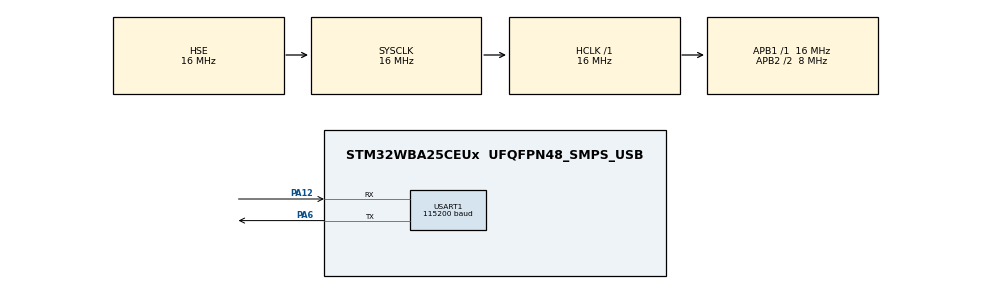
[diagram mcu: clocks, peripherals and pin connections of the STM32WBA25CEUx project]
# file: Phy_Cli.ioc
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CORTEX_M33_NS.userName=CORTEX_M33
LPDMA1.DESTINC_LPDMACH1=DMA_DINC_INCREMENTED
LPDMA1.DIRECTION_LPDMACH0=DMA_MEMORY_TO_PERIPH
LPDMA1.DIRECTION_LPDMACH1=DMA_PERIPH_TO_MEMORY
LPDMA1.IPHANDLE_LPDMACH0-SIMPLEREQUEST_LPDMACH0=__NULL
LPDMA1.IPHANDLE_LPDMACH1-SIMPLEREQUEST_LPDMACH1=__NULL
LPDMA1.REQUEST_LPDMACH0=LPDMA1_REQUEST_USART1_TX
LPDMA1.REQUEST_LPDMACH1=LPDMA1_REQUEST_USART1_RX
LPDMA1.SRCINC_LPDMACH0=DMA_SINC_INCREMENTED
Mcu.Family=STM32WBA
Mcu.Name=STM32WBA25CEUx
Mcu.Package=UFQFPN48_SMPS_USB
NVIC.LPDMA1_Channel0_IRQn=true\:6\:0\:true\:false\:true\:true\:true\:true
NVIC.LPDMA1_Channel1_IRQn=true\:2\:0\:true\:false\:true\:true\:true\:true
NVIC.PriorityGroup=NVIC_PRIORITYGROUP_4
NVIC.RADIO_IRQn=true\:0\:0\:false\:false\:true\:false\:false\:true
NVIC.RCC_IRQn=true\:1\:0\:false\:false\:true\:false\:false\:true
NVIC.RTC_IRQn=true\:4\:0\:false\:false\:true\:false\:true\:true
NVIC.USART1_IRQn=true\:7\:0\:true\:false\:true\:true\:true\:true
OSC_IN.Mode=HSE-External-Oscillator
OSC_IN.Signal=RCC_OSC_IN
OSC_OUT.Mode=HSE-External-Oscillator
OSC_OUT.Signal=RCC_OSC_OUT
PA12.GPIO_PuPd=GPIO_PULLUP
PA12.GPIO_Speed=GPIO_SPEED_FREQ_HIGH
PA12.Mode=Asynchronous
PA12.Signal=USART1_RX
PA13\ (JTMS/SWDIO).Signal=DEBUG_JTMS-SWDIO
PA14\ (JTCK/SWCLK).Signal=DEBUG_JTCK-SWCLK
PA6.GPIO_PuPd=GPIO_PULLUP
PA6.GPIO_Speed=GPIO_SPEED_FREQ_HIGH
PA6.Mode=Asynchronous
PA6.Signal=USART1_TX
PC14-OSC32_IN.Mode=LSE-External-Oscillator
PC14-OSC32_IN.Signal=RCC_OSC32_IN
PC15-OSC32_OUT.Mode=LSE-External-Oscillator
PC15-OSC32_OUT.Signal=RCC_OSC32_OUT
ProjectManager.HeapSize=0x200
ProjectManager.StackSize=0x400
ProjectManager.TargetToolchain=STM32CubeIDE
RAMCFG.Instance-RAMCFG1_Activate=RAMCFG_SRAM1
RCC.ADCFreq_Value=16000000
RCC.AHBFreq_Value=16000000
RCC.APB1Freq_Value=16000000
RCC.APB1TimFreq_Value=16000000
RCC.APB2CLKDivider=RCC_HCLK_DIV2
RCC.APB2Freq_Value=8000000
RCC.APB2TimFreq_Value=16000000
RCC.CortexCLockSelectionVirtual=RCC_SYSTICKCLKSOURCE_LSE
RCC.CortexFreq_Value=32768
RCC.HCLKFreq_Value=16000000
RCC.HSE_VALUE=16000000
RCC.HSI_VALUE=16000000
RCC.I2C1CLockSelection=RCC_I2C1CLKSOURCE_HSI
RCC.I2C3CLockSelection=RCC_I2C3CLKSOURCE_HSI
RCC.LPUART1CLockSelectionVirtual=RCC_LPUART1CLKSOURCE_HSI
RCC.PLLFRACN=0
RCC.PLLN=8
RCC.PLLSourceVirtual=RCC_PLLSOURCE_HSE
RCC.PWR_Regulator_Voltage_Scale=PWR_REGULATOR_VOLTAGE_SCALE2
RCC.RSTClockSelectionVirtual=RCC_RADIOSTCLKSOURCE_LSE
RCC.RTCClockSelection=RCC_RTCCLKSOURCE_LSE
RCC.SPI3CLockSelection=RCC_SPI3CLKSOURCE_HSI
RCC.SYSCLKFreq_VALUE=16000000
RCC.SYSCLKSourceVirtual=RCC_SYSCLKSOURCE_HSE
RCC.SupplySource=PWR_SMPS_SUPPLY
RCC.USART1CLockSelectionVirtual=RCC_USART1CLKSOURCE_HSI
RCC.VCOOutputFreq_Value=128000000
RTC.Alarm-Alarm\ A=RTC_ALARM_A
STM32_WPAN.BSP.number=1
STM32_WPAN.CFG_DEBUGGER_LEVEL=0
STM32_WPAN.CFG_LOG_INSERT_COLOR_INSIDE_THE_TRACE=0
STM32_WPAN.CFG_LOG_INSERT_EOL_INSIDE_THE_TRACE=0
STM32_WPAN.CFG_LOG_SUPPORTED=0
STM32_WPAN.CFG_LPM_LEVEL=0
STM32_WPAN.CFG_PHY_CLI_SUPPORTED=1
STM32_WPAN.CFG_RF_TX_POWER_TABLE_ID=0
STM32_WPAN.CFG_RT_DEBUG_DTB=0
STM32_WPAN.RADIO_INTR_PRIO_LOW=5
STM32_WPAN.USE_TEMPERATURE_BASED_RADIO_CALIBRATION=0
STM32_WPAN0.BSP.STBoard=false
STM32_WPAN0.BSP.api=Unknown
STM32_WPAN0.BSP.instance=USART1
STM32_WPAN0.BSP.ip=(LPU|US)ART
STM32_WPAN0.BSP.mode=Single Wire \\(Half-Duplex\\)|Asynchronous
STM32_WPAN0.BSP.name=Serial Link for Logs
STM32_WPAN0.BSP.solution=USART1
USART1.BaudRate=115200
USART1.FIFOMode=FIFOMODE_ENABLE
USART1.Mode=MODE_TX_RX
USART1.OneBitSampling=UART_ONE_BIT_SAMPLE_DISABLE
USART1.OverSampling=UART_OVERSAMPLING_8
USART1.Parity=PARITY_NONE
USART1.StopBits=STOPBITS_1
USART1.VirtualMode-Asynchronous=VM_ASYNC
USART1.WordLength=WORDLENGTH_8B
VP_ADV_TRACE_VS_ADV_TRACE.Mode=ADV_TRACE_Enabled
VP_COMMON_WPAN_VS_Utility_Common_1.0.0_1.0.0.Mode=Utility_Common
VP_CORTEX_M33_NS_VS_Ext.Mode=External_Mode
VP_CRC_VS_CRC.Mode=CRC_Activate
VP_ICACHE_VS_ICACHE.Mode=DirectMappedCache
VP_LPDMA1_VS_LPDMACH0.Mode=SIMPLEREQUEST_LPDMACH0
VP_LPDMA1_VS_LPDMACH1.Mode=SIMPLEREQUEST_LPDMACH1
VP_MISC_VS_MISC.Mode=MISC_Enabled
VP_PWR_VS_SECSignals.Mode=Security/Privilege
VP_RAMCFG_VS_RAMCFG1.Mode=RAMCFG1_Activate
VP_RF_VS_RF.Mode=RF_Activate
VP_RNG_VS_RNG.Mode=RNG_Activate
VP_RTC_VS_RTC_Activate.Mode=RTC_Enabled
VP_RTC_VS_RTC_Alarm_A_Intern.Mode=Alarm A
VP_RTC_VS_RTC_Calendar.Mode=RTC_Calendar
VP_SEQUENCER_VS_SEQUENCER.Mode=SEQUENCER_Enabled
VP_STM32_WPAN_VS_mac_802_15_4_SKELETON.Mode=mac_802_15_4_Skeleton
VP_TIMER_VS_TIMER.Mode=TIMER_Enabled
VP_TINY_LPM_VS_TINY_LPM.Mode=TINY_LPM_Enabled
board=NUCLEO-WBA25CE1

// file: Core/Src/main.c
/* USER CODE BEGIN Header */
/**
  ******************************************************************************
  * @file           : main.c
  * @brief          : Main program body
  ******************************************************************************
  * @attention
  *
  * Copyright (c) 2026 STMicroelectronics.
  * All rights reserved.
  *
  * This software is licensed under terms that can be found in the LICENSE file
  * in the root directory of this software component.
  * If no LICENSE file comes with this software, it is provided AS-IS.
  *
  ******************************************************************************
  */
/* USER CODE END Header */
#include "main.h"

RAMCFG_HandleTypeDef hramcfg_SRAM1;

RNG_HandleTypeDef hrng;

RTC_HandleTypeDef hrtc;

UART_HandleTypeDef huart1;
DMA_HandleTypeDef handle_LPDMA1_Channel0;
DMA_HandleTypeDef handle_LPDMA1_Channel1;

void SystemClock_Config(void);
void PeriphCommonClock_Config(void);
static void MX_GPIO_Init(void);

int main(void)
{

  /* MCU Configuration--------------------------------------------------------*/

  /* Reset of all peripherals, Initializes the Flash interface and the Systick. */
  HAL_Init();
  /* Config code for STM32_WPAN (HSE Tuning must be done before system clock configuration) */
  MX_APPE_Config();

  /* Configure the system clock */
  SystemClock_Config();

  /* Configure the peripherals common clocks */
  PeriphCommonClock_Config();

  /* Initialize all configured peripherals */
  MX_GPIO_Init();
  MX_LPDMA1_Init();
  MX_RAMCFG_Init();
  MX_RTC_Init();
  MX_USART1_UART_Init();
  MX_ICACHE_Init();
  MX_RNG_Init();

  /* Init code for STM32_WPAN */
  MX_APPE_Init(NULL);

  /* Infinite loop */
  while (1)
  {
    MX_APPE_Process();

  }
}

void SystemClock_Config(void)
{
  RCC_OscInitTypeDef RCC_OscInitStruct = {0};
  RCC_ClkInitTypeDef RCC_ClkInitStruct = {0};

  /** Supply configuration update enable
  */
  HAL_PWREx_ConfigSupply(PWR_SMPS_SUPPLY);

  /** Configure the main internal regulator output voltage
  */
  if (HAL_PWREx_ControlVoltageScaling(PWR_REGULATOR_VOLTAGE_SCALE2) != HAL_OK)
  {
    Error_Handler();
  }

  /** Configure LSE Drive Capability
  */
  HAL_PWR_EnableBkUpAccess();
  __HAL_RCC_LSEDRIVE_CONFIG(RCC_LSEDRIVE_MEDIUMLOW);

  /** Initializes the CPU, AHB and APB busses clocks
  */
  RCC_OscInitStruct.OscillatorType = RCC_OSCILLATORTYPE_HSI|RCC_OSCILLATORTYPE_HSE
                              |RCC_OSCILLATORTYPE_LSE;
  RCC_OscInitStruct.HSEState = RCC_HSE_ON;
  RCC_OscInitStruct.HSEDiv = RCC_HSE_DIV1;
  RCC_OscInitStruct.LSEState = RCC_LSE_ON;
  RCC_OscInitStruct.HSIState = RCC_HSI_ON;
  RCC_OscInitStruct.HSICalibrationValue = RCC_HSICALIBRATION_DEFAULT;
  RCC_OscInitStruct.PLL1.PLLState = RCC_PLL_NONE;
  if (HAL_RCC_OscConfig(&RCC_OscInitStruct) != HAL_OK)
  {
    Error_Handler();
  }

  /** Initializes the CPU, AHB and APB busses clocks
  */
  RCC_ClkInitStruct.ClockType = RCC_CLOCKTYPE_HCLK|RCC_CLOCKTYPE_SYSCLK
                              |RCC_CLOCKTYPE_PCLK1|RCC_CLOCKTYPE_PCLK2
                              |RCC_CLOCKTYPE_PCLK7|RCC_CLOCKTYPE_HCLK5;
  RCC_ClkInitStruct.SYSCLKSource = RCC_SYSCLKSOURCE_HSE;
  RCC_ClkInitStruct.AHBCLKDivider = RCC_SYSCLK_DIV1;
  RCC_ClkInitStruct.APB1CLKDivider = RCC_HCLK_DIV1;
  RCC_ClkInitStruct.APB2CLKDivider = RCC_HCLK_DIV2;
  RCC_ClkInitStruct.APB7CLKDivider = RCC_HCLK_DIV1;
  RCC_ClkInitStruct.AHB5_PLL1_CLKDivider = RCC_SYSCLK_PLL1_DIV1;
  RCC_ClkInitStruct.AHB5_HSEHSI_CLKDivider = RCC_SYSCLK_HSEHSI_DIV1;

  if (HAL_RCC_ClockConfig(&RCC_ClkInitStruct, FLASH_LATENCY_1) != HAL_OK)
  {
    Error_Handler();
  }

   /* Select SysTick source clock */
  HAL_SYSTICK_CLKSourceConfig(SYSTICK_CLKSOURCE_LSE);

   /* Re-Initialize Tick with new clock source */
  if (HAL_InitTick(TICK_INT_PRIORITY) != HAL_OK)
  {
    Error_Handler();
  }
}

void PeriphCommonClock_Config(void)
{
  RCC_PeriphCLKInitTypeDef PeriphClkInit = {0};

  /** Initializes the peripherals clock
  */
  PeriphClkInit.PeriphClockSelection = RCC_PERIPHCLK_RADIOST;
  PeriphClkInit.RadioSlpTimClockSelection = RCC_RADIOSTCLKSOURCE_LSE;
  if (HAL_RCCEx_PeriphCLKConfig(&PeriphClkInit) != HAL_OK)
  {
    Error_Handler();
  }
}

void MX_ICACHE_Init(void)
{

  /** Enable instruction cache in 1-way (direct mapped cache)
  */
  LL_ICACHE_SetMode(LL_ICACHE_1WAY);
  LL_ICACHE_Enable();

}

void MX_LPDMA1_Init(void)
{

  /* Peripheral clock enable */
  __HAL_RCC_LPDMA1_CLK_ENABLE();

  /* LPDMA1 interrupt Init */
    HAL_NVIC_SetPriority(LPDMA1_Channel0_IRQn, 6, 0);
    HAL_NVIC_EnableIRQ(LPDMA1_Channel0_IRQn);
    HAL_NVIC_SetPriority(LPDMA1_Channel1_IRQn, 2, 0);
    HAL_NVIC_EnableIRQ(LPDMA1_Channel1_IRQn);

}

void MX_RAMCFG_Init(void)
{

  /** Initialize RAMCFG SRAM1
  */
  hramcfg_SRAM1.Instance = RAMCFG_SRAM1;
  if (HAL_RAMCFG_Init(&hramcfg_SRAM1) != HAL_OK)
  {
    Error_Handler();
  }
  if (HAL_RAMCFG_ConfigWaitState(&hramcfg_SRAM1, RAMCFG_WAITSTATE_1) != HAL_OK)
  {
    Error_Handler();
  }

}

void MX_RNG_Init(void)
{

  hrng.Instance = RNG;
  hrng.Init.ClockErrorDetection = RNG_CED_DISABLE;
  if (HAL_RNG_Init(&hrng) != HAL_OK)
  {
    Error_Handler();
  }

}

void MX_RTC_Init(void)
{

  RTC_PrivilegeStateTypeDef privilegeState = {0};
  RTC_AlarmTypeDef sAlarm = {0};

  /** Initialize RTC Only
  */
  hrtc.Instance = RTC;
  hrtc.Init.AsynchPrediv = 31;
  hrtc.Init.OutPut = RTC_OUTPUT_DISABLE;
  hrtc.Init.OutPutRemap = RTC_OUTPUT_REMAP_NONE;
  hrtc.Init.OutPutPolarity = RTC_OUTPUT_POLARITY_HIGH;
  hrtc.Init.OutPutType = RTC_OUTPUT_TYPE_OPENDRAIN;
  hrtc.Init.OutPutPullUp = RTC_OUTPUT_PULLUP_NONE;
  hrtc.Init.BinMode = RTC_BINARY_ONLY;
  if (HAL_RTC_Init(&hrtc) != HAL_OK)
  {
    Error_Handler();
  }
  privilegeState.rtcPrivilegeFull = RTC_PRIVILEGE_FULL_NO;
  privilegeState.backupRegisterPrivZone = RTC_PRIVILEGE_BKUP_ZONE_NONE;
  privilegeState.backupRegisterStartZone2 = RTC_BKP_DR0;
  privilegeState.backupRegisterStartZone3 = RTC_BKP_DR0;
  if (HAL_RTCEx_PrivilegeModeSet(&hrtc, &privilegeState) != HAL_OK)
  {
    Error_Handler();
  }

  /** Initialize RTC and set the Time and Date
  */
  if (HAL_RTCEx_SetSSRU_IT(&hrtc) != HAL_OK)
  {
    Error_Handler();
  }

  /** Enable the Alarm A
  */
  sAlarm.BinaryAutoClr = RTC_ALARMSUBSECONDBIN_AUTOCLR_NO;
  sAlarm.AlarmTime.SubSeconds = 0x0;
  sAlarm.AlarmMask = RTC_ALARMMASK_NONE;
  sAlarm.AlarmSubSecondMask = RTC_ALARMSUBSECONDBINMASK_NONE;
  sAlarm.Alarm = RTC_ALARM_A;
  sAlarm.FlagAutoClr = ALARM_FLAG_AUTOCLR_DISABLE;
  if (HAL_RTC_SetAlarm_IT(&hrtc, &sAlarm, RTC_FORMAT_BCD) != HAL_OK)
  {
    Error_Handler();
  }

}

void MX_USART1_UART_Init(void)
{

  huart1.Instance = USART1;
  huart1.Init.BaudRate = 115200;
  huart1.Init.WordLength = UART_WORDLENGTH_8B;
  huart1.Init.StopBits = UART_STOPBITS_1;
  huart1.Init.Parity = UART_PARITY_NONE;
  huart1.Init.Mode = UART_MODE_TX_RX;
  huart1.Init.HwFlowCtl = UART_HWCONTROL_NONE;
  huart1.Init.OverSampling = UART_OVERSAMPLING_8;
  huart1.Init.OneBitSampling = UART_ONE_BIT_SAMPLE_DISABLE;
  huart1.Init.ClockPrescaler = UART_PRESCALER_DIV1;
  huart1.AdvancedInit.AdvFeatureInit = UART_ADVFEATURE_NO_INIT;
  if (HAL_UART_Init(&huart1) != HAL_OK)
  {
    Error_Handler();
  }
  if (HAL_UARTEx_SetTxFifoThreshold(&huart1, UART_TXFIFO_THRESHOLD_1_8) != HAL_OK)
  {
    Error_Handler();
  }
  if (HAL_UARTEx_SetRxFifoThreshold(&huart1, UART_RXFIFO_THRESHOLD_1_8) != HAL_OK)
  {
    Error_Handler();
  }
  if (HAL_UARTEx_EnableFifoMode(&huart1) != HAL_OK)
  {
    Error_Handler();
  }

}

static void MX_GPIO_Init(void)
{

  /* GPIO Ports Clock Enable */
  __HAL_RCC_GPIOA_CLK_ENABLE();
  __HAL_RCC_GPIOC_CLK_ENABLE();

}

void Error_Handler(void)
{
  __disable_irq();
  while (1)
  {
  }
}
#ifdef USE_FULL_ASSERT
/**
  * @brief  Reports the name of the source file and the source line number
  *         where the assert_param error has occurred.
  * @param  file: pointer to the source file name
  * @param  line: assert_param error line source number
  * @retval None
  */
void assert_failed(uint8_t *file, uint32_t line)
{
  /* USER CODE BEGIN 6 */
  /* User can add his own implementation to report the file name and line number,
     ex: printf("Wrong parameters value: file %s on line %d\r\n", file, line) */
  Error_Handler();
  /* USER CODE END 6 */
}
#endif /* USE_FULL_ASSERT */
